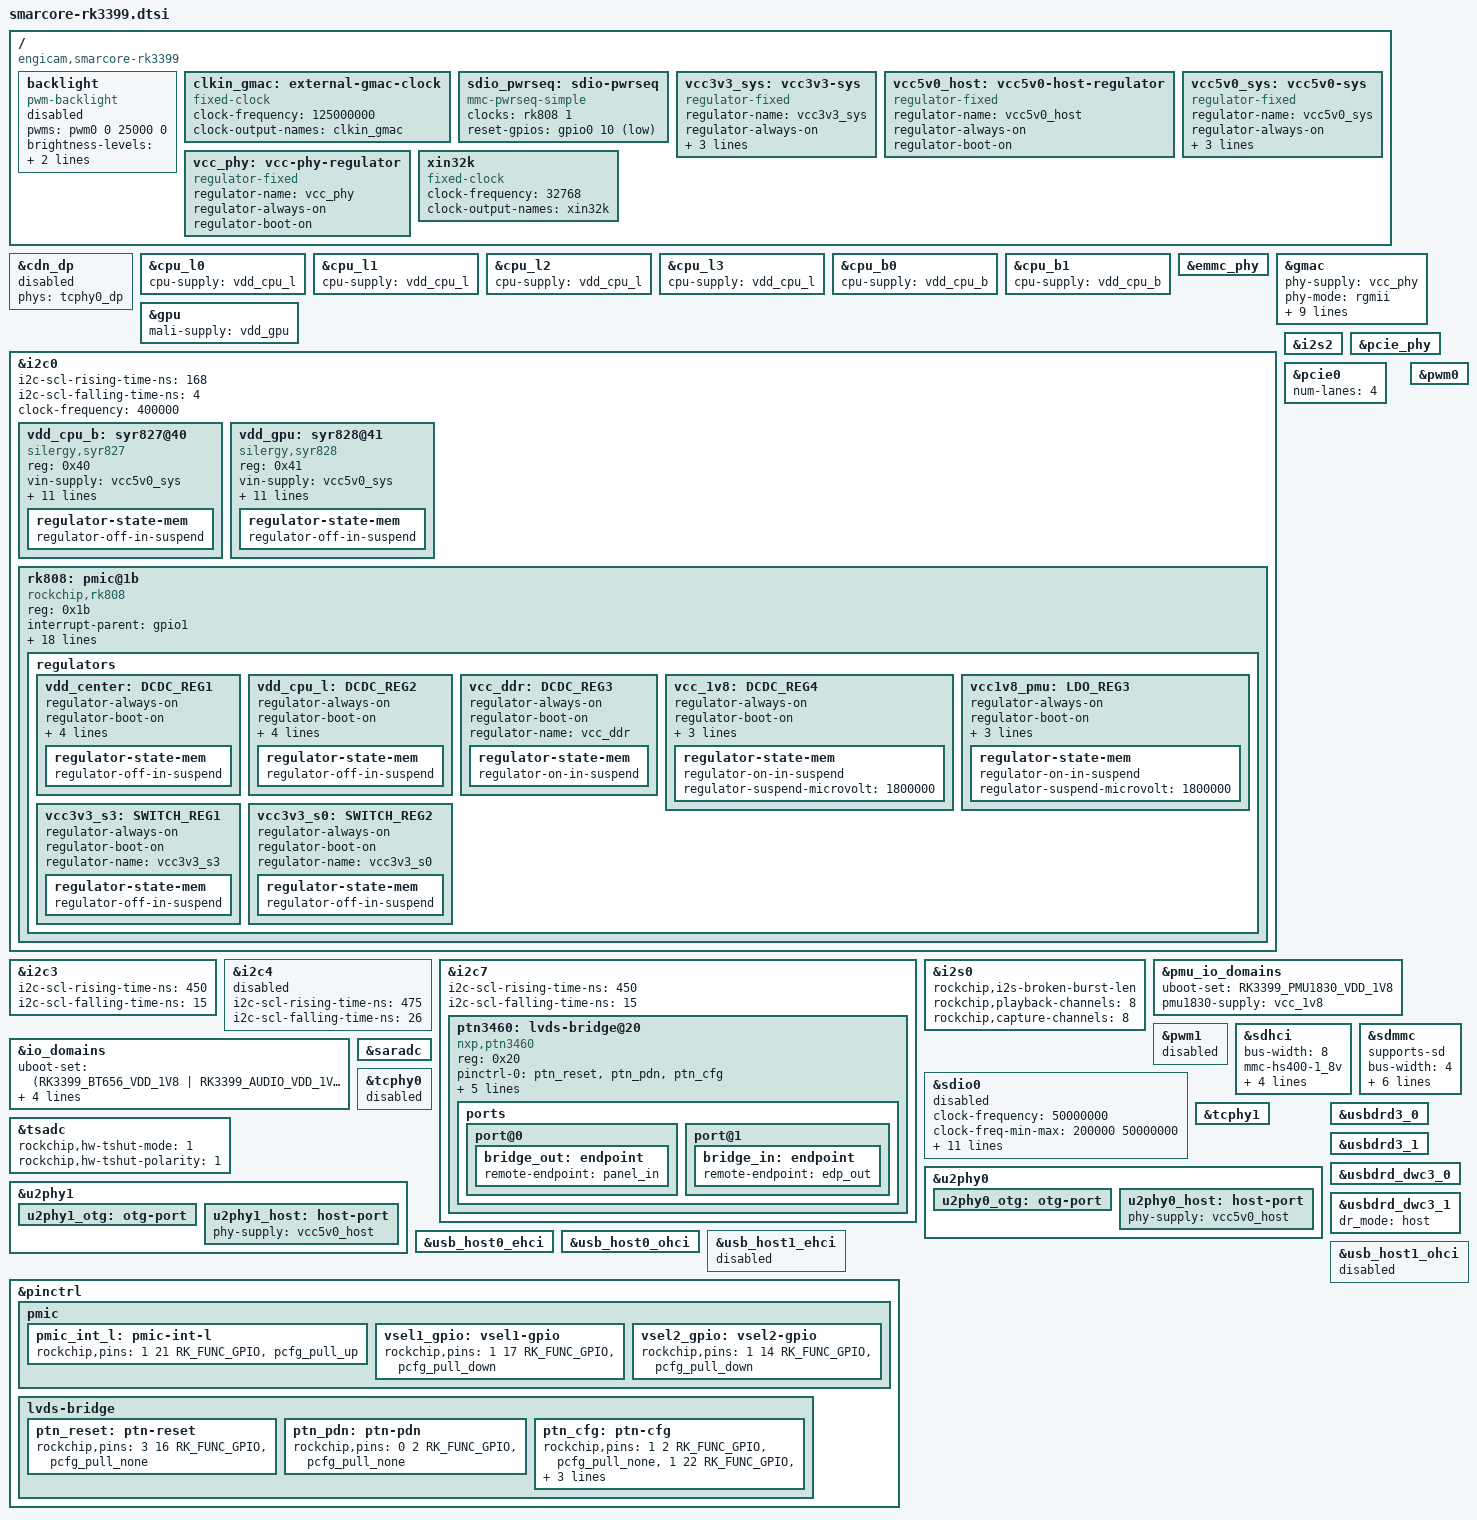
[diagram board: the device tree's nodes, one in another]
/*
 * Copyright (c) 2020 Engicam srl
 *
 * based on:
 * Copyright (c) 2016 Fuzhou Rockchip Electronics Co., Ltd
 *
 * This file is dual-licensed: you can use it either under the terms
 * of the GPL or the X11 license, at your option. Note that this dual
 * licensing only applies to this file, and not this project as a
 * whole.
 *
 *  a) This file is free software; you can redistribute it and/or
 *     modify it under the terms of the GNU General Public License as
 *     published by the Free Software Foundation; either version 2 of the
 *     License, or (at your option) any later version.
 *
 *     This file is distributed in the hope that it will be useful,
 *     but WITHOUT ANY WARRANTY; without even the implied warranty of
 *     MERCHANTABILITY or FITNESS FOR A PARTICULAR PURPOSE.  See the
 *     GNU General Public License for more details.
 *
 * Or, alternatively,
 *
 *  b) Permission is hereby granted, free of charge, to any person
 *     obtaining a copy of this software and associated documentation
 *     files (the "Software"), to deal in the Software without
 *     restriction, including without limitation the rights to use,
 *     copy, modify, merge, publish, distribute, sublicense, and/or
 *     sell copies of the Software, and to permit persons to whom the
 *     Software is furnished to do so, subject to the following
 *     conditions:
 *
 *     The above copyright notice and this permission notice shall be
 *     included in all copies or substantial portions of the Software.
 *
 *     THE SOFTWARE IS PROVIDED "AS IS", WITHOUT WARRANTY OF ANY KIND,
 *     EXPRESS OR IMPLIED, INCLUDING BUT NOT LIMITED TO THE WARRANTIES
 *     OF MERCHANTABILITY, FITNESS FOR A PARTICULAR PURPOSE AND
 *     NONINFRINGEMENT. IN NO EVENT SHALL THE AUTHORS OR COPYRIGHT
 *     HOLDERS BE LIABLE FOR ANY CLAIM, DAMAGES OR OTHER LIABILITY,
 *     WHETHER IN AN ACTION OF CONTRACT, TORT OR OTHERWISE, ARISING
 *     FROM, OUT OF OR IN CONNECTION WITH THE SOFTWARE OR THE USE OR
 *     OTHER DEALINGS IN THE SOFTWARE.
 */

#include "dt-bindings/pwm/pwm.h"
#include <dt-bindings/soc/rockchip-io-domain.h>
#include "rk3399.dtsi"
#include "../rockchip/rk3399-opp.dtsi"

/ {
	compatible = "engicam,smarcore-rk3399", "rockchip,rk3399";

	backlight: backlight {
		status = "disabled";
		compatible = "pwm-backlight";
		pwms = <&pwm0 0 25000 0>;
		brightness-levels = <
			  0   1   2   3   4   5   6   7
			  8   9  10  11  12  13  14  15
			 16  17  18  19  20  21  22  23
			 24  25  26  27  28  29  30  31
			 32  33  34  35  36  37  38  39
			 40  41  42  43  44  45  46  47
			 48  49  50  51  52  53  54  55
			 56  57  58  59  60  61  62  63
			 64  65  66  67  68  69  70  71
			 72  73  74  75  76  77  78  79
			 80  81  82  83  84  85  86  87
			 88  89  90  91  92  93  94  95
			 96  97  98  99 100 101 102 103
			104 105 106 107 108 109 110 111
			112 113 114 115 116 117 118 119
			120 121 122 123 124 125 126 127
			128 129 130 131 132 133 134 135
			136 137 138 139 140 141 142 143
			144 145 146 147 148 149 150 151
			152 153 154 155 156 157 158 159
			160 161 162 163 164 165 166 167
			168 169 170 171 172 173 174 175
			176 177 178 179 180 181 182 183
			184 185 186 187 188 189 190 191
			192 193 194 195 196 197 198 199
			200 201 202 203 204 205 206 207
			208 209 210 211 212 213 214 215
			216 217 218 219 220 221 222 223
			224 225 226 227 228 229 230 231
			232 233 234 235 236 237 238 239
			240 241 242 243 244 245 246 247
			248 249 250 251 252 253 254 255>;
		default-brightness-level = <200>;
	};

	clkin_gmac: external-gmac-clock {
		compatible = "fixed-clock";
		clock-frequency = <125000000>;
		clock-output-names = "clkin_gmac";
		#clock-cells = <0>;
	};

	sdio_pwrseq: sdio-pwrseq {
		compatible = "mmc-pwrseq-simple";
		clocks = <&rk808 1>;
		clock-names = "ext_clock";
//		pinctrl-names = "default";
//		pinctrl-0 = <&wifi_enable_h>;

		/*
		 * On the module itself this is one of these (depending
		 * on the actual card populated):
		 * - SDIO_RESET_L_WL_REG_ON
		 * - PDN (power down when low)
		 */
		reset-gpios = <&gpio0 10 GPIO_ACTIVE_LOW>; /* GPIO0_B2 */
	};

	vcc3v3_sys: vcc3v3-sys {
		compatible = "regulator-fixed";
		regulator-name = "vcc3v3_sys";
		regulator-always-on;
		regulator-boot-on;
		regulator-min-microvolt = <3300000>;
		regulator-max-microvolt = <3300000>;
	};

	vcc5v0_host: vcc5v0-host-regulator {
		compatible = "regulator-fixed";
		regulator-name = "vcc5v0_host";
		regulator-always-on;
		regulator-boot-on;
	};

	vcc5v0_sys: vcc5v0-sys {
		compatible = "regulator-fixed";
		regulator-name = "vcc5v0_sys";
		regulator-always-on;
		regulator-boot-on;
		regulator-min-microvolt = <5000000>;
		regulator-max-microvolt = <5000000>;
	};

	vcc_phy: vcc-phy-regulator {
		compatible = "regulator-fixed";
		regulator-name = "vcc_phy";
		regulator-always-on;
		regulator-boot-on;
	};

	xin32k: xin32k {
		compatible = "fixed-clock";
		clock-frequency = <32768>;
		clock-output-names = "xin32k";
		#clock-cells = <0>;
	};
};

&cdn_dp {
	phys = <&tcphy0_dp>;
	status = "disabled";
};

&cpu_l0 {
	cpu-supply = <&vdd_cpu_l>;
};

&cpu_l1 {
	cpu-supply = <&vdd_cpu_l>;
};

&cpu_l2 {
	cpu-supply = <&vdd_cpu_l>;
};

&cpu_l3 {
	cpu-supply = <&vdd_cpu_l>;
};

&cpu_b0 {
	cpu-supply = <&vdd_cpu_b>;
};

&cpu_b1 {
	cpu-supply = <&vdd_cpu_b>;
};

&emmc_phy {
	status = "okay";
};

&gmac {
	phy-supply = <&vcc_phy>;
	phy-mode = "rgmii";
	clock_in_out = "input";
	snps,reset-gpio = <&gpio3 15 GPIO_ACTIVE_LOW>;
	snps,reset-active-low;
	snps,reset-delays-us = <0 10000 50000>;
	assigned-clocks = <&cru SCLK_RMII_SRC>;
	assigned-clock-parents = <&clkin_gmac>;
	pinctrl-names = "default";
	pinctrl-0 = <&rgmii_pins>;
	tx_delay = <0x0>;
	rx_delay = <0x0>;
	status = "okay";
};

&gpu {
	status = "okay";
	mali-supply = <&vdd_gpu>;
};

&i2c0 {
	status = "okay";
	i2c-scl-rising-time-ns = <168>;
	i2c-scl-falling-time-ns = <4>;
	clock-frequency = <400000>;

	vdd_cpu_b: syr827@40 {
		compatible = "silergy,syr827";
		reg = <0x40>;
		vin-supply = <&vcc5v0_sys>;
		regulator-compatible = "fan53555-reg";
		pinctrl-names = "default";
		pinctrl-0 = <&vsel1_gpio>;
		vsel-gpios = <&gpio1 17 GPIO_ACTIVE_HIGH>;
		regulator-name = "vdd_cpu_b";
		regulator-min-microvolt = <712500>;
		regulator-max-microvolt = <1500000>;
		regulator-ramp-delay = <1000>;
		fcs,suspend-voltage-selector = <1>;
		regulator-always-on;
		regulator-boot-on;
		regulator-initial-state = <3>;
			regulator-state-mem {
			regulator-off-in-suspend;
		};
	};

	vdd_gpu: syr828@41 {
		compatible = "silergy,syr828";
		reg = <0x41>;
		vin-supply = <&vcc5v0_sys>;
		regulator-compatible = "fan53555-reg";
		pinctrl-names = "default";
		pinctrl-0 = <&vsel2_gpio>;
		vsel-gpios = <&gpio1 14 GPIO_ACTIVE_HIGH>;
		regulator-name = "vdd_gpu";
		regulator-min-microvolt = <712500>;
		regulator-max-microvolt = <1500000>;
		regulator-ramp-delay = <1000>;
		fcs,suspend-voltage-selector = <1>;
		regulator-always-on;
		regulator-boot-on;
		regulator-initial-state = <3>;
			regulator-state-mem {
			regulator-off-in-suspend;
		};
	};

	rk808: pmic@1b {
		compatible = "rockchip,rk808";
		reg = <0x1b>;
		interrupt-parent = <&gpio1>;
		interrupts = <21 IRQ_TYPE_LEVEL_LOW>;
		pinctrl-names = "default";
		pinctrl-0 = <&pmic_int_l>;
		rockchip,system-power-controller;
		wakeup-source;
		#clock-cells = <1>;
		clock-output-names = "rk808-clkout1", "rk808-clkout2";

		vcc1-supply = <&vcc5v0_sys>;
		vcc2-supply = <&vcc5v0_sys>;
		vcc3-supply = <&vcc5v0_sys>;
		vcc4-supply = <&vcc5v0_sys>;
		vcc6-supply = <&vcc3v3_sys>;
		vcc7-supply = <&vcc3v3_sys>;
		vcc8-supply = <&vcc3v3_sys>;
		vcc9-supply = <&vcc3v3_sys>;
		vcc10-supply = <&vcc3v3_sys>;
		vcc11-supply = <&vcc3v3_sys>;
		vcc12-supply = <&vcc3v3_sys>;
		vddio-supply = <&vcc_1v8>;

		regulators {
			vdd_center: DCDC_REG1 {
				regulator-always-on;
				regulator-boot-on;
				regulator-min-microvolt = <750000>;
				regulator-max-microvolt = <1350000>;
				regulator-ramp-delay = <6001>;
				regulator-name = "vdd_center";
				regulator-state-mem {
					regulator-off-in-suspend;
				};
			};

			vdd_cpu_l: DCDC_REG2 {
				regulator-always-on;
				regulator-boot-on;
				regulator-min-microvolt = <750000>;
				regulator-max-microvolt = <1350000>;
				regulator-ramp-delay = <6001>;
				regulator-name = "vdd_cpu_l";
				regulator-state-mem {
					regulator-off-in-suspend;
				};
			};

			vcc_ddr: DCDC_REG3 {
				regulator-always-on;
				regulator-boot-on;
				regulator-name = "vcc_ddr";
				regulator-state-mem {
					regulator-on-in-suspend;
				};
			};

			vcc_1v8: DCDC_REG4 {
				regulator-always-on;
				regulator-boot-on;
				regulator-min-microvolt = <1800000>;
				regulator-max-microvolt = <1800000>;
				regulator-name = "vcc_1v8";
				regulator-state-mem {
					regulator-on-in-suspend;
					regulator-suspend-microvolt = <1800000>;
				};
			};

			vcc1v8_pmu: LDO_REG3 {
				regulator-always-on;
				regulator-boot-on;
				regulator-min-microvolt = <1800000>;
				regulator-max-microvolt = <1800000>;
				regulator-name = "vcc1v8_pmu";
				regulator-state-mem {
					regulator-on-in-suspend;
					regulator-suspend-microvolt = <1800000>;
				};
			};


			vcc3v3_s3: SWITCH_REG1 {
				regulator-always-on;
				regulator-boot-on;
				regulator-name = "vcc3v3_s3";
				regulator-state-mem {
					regulator-off-in-suspend;
				};
			};

			vcc3v3_s0: SWITCH_REG2 {
				regulator-always-on;
				regulator-boot-on;
				regulator-name = "vcc3v3_s0";
				regulator-state-mem {
					regulator-off-in-suspend;
				};
			};
		};
	};
};

&i2c3 {
	status = "okay";
	i2c-scl-rising-time-ns = <450>;
	i2c-scl-falling-time-ns = <15>;
};

&i2c4 {
	status = "disabled";
	i2c-scl-rising-time-ns = <475>;
	i2c-scl-falling-time-ns = <26>;

};

&i2c7 {
	status = "okay";
	i2c-scl-rising-time-ns = <450>;
	i2c-scl-falling-time-ns = <15>;

	ptn3460: lvds-bridge@20 {
		compatible = "nxp,ptn3460";
		reg = <0x20>;
		pinctrl-names = "default";
		pinctrl-0 = <&ptn_reset &ptn_pdn &ptn_cfg>;
		powerdown-gpios = <&gpio0 2 GPIO_ACTIVE_HIGH>;
		reset-gpios = <&gpio3 16 GPIO_ACTIVE_HIGH>;
		edid-emulation = <0>;
		enable-gpios = <&gpio1 2 GPIO_ACTIVE_LOW>, /* CFG1 */
				<&gpio1 22 GPIO_ACTIVE_LOW>, /* CFG2 */
				<&gpio1 18 GPIO_ACTIVE_LOW>, /* CFG3 */
				<&gpio1 20 GPIO_ACTIVE_LOW>; /* CFG4 */

		ports {
			#address-cells = <1>;
			#size-cells = <0>;

			port@0 {
				bridge_out: endpoint {
					remote-endpoint = <&panel_in>;
				};
			};

			port@1 {
				bridge_in: endpoint {
					remote-endpoint = <&edp_out>;
				};
			};
		};
	};

};

&i2s0 {
	status = "okay";
	rockchip,i2s-broken-burst-len;
	rockchip,playback-channels = <8>;
	rockchip,capture-channels = <8>;
	#sound-dai-cells = <0>;
};

&i2s2 {
	#sound-dai-cells = <0>;
	status = "okay";
};

&io_domains {
	status = "okay";

	/*
	 * If the uboot use rkdevelop branch, the io-domain is not set
	 * during uboot phase, it will cause the io voltage is not suit for
	 * the hardware,maybe will damage the io of rk3399, so we add
	 * uboot-set value to make sure the value is same with the kernel,
	 * ofcause you must make sure firstly the value here is suit for your
	 * hardware. The available value is defined in
	 * include/dt-bindings/soc/rockchip-io-domain.h, they are
	 * also list here for more convenient configuration:
	 * bt656-supply: RK3399_BT656_VDD_1V8 or RK3399_BT656_VDD_3V3
	 * audio-supply: RK3399_AUDIO_VDD_1V8 or RK3399_AUDIO_VDD_3V3
	 * gpio1830-supply: RK3399_GPIO1833_VDD_1V8 or RK3399_GPIO1833_VDD_3V3
	 * sdmmc-supply: don't need to configure because the voltage
	 *                       is set in source code during runtime.
	 * NOTE:
	 * 1. The value in uboot-set must be enclosed in "()", otherwise will
	 *     cause compile error.
	 * 2. The uboot-set configuration must be cooperated with submit
	 *     in u-boot.
	 */

	uboot-set = <(RK3399_BT656_VDD_1V8 | RK3399_AUDIO_VDD_1V8 |
				RK3399_GPIO1833_VDD_1V8 | RK3399_SDMMC_VDD_1V8)>;
	bt656-supply = <&vcc_1v8>;		/* bt656_gpio2ab_ms */
	audio-supply = <&vcc_1v8>;	/* audio_gpio3d4a_ms */
	sdmmc-supply = <&vcc_1v8>;		/* sdmmc_gpio4b_ms */
	gpio1830-supply = <&vcc_1v8>;		/* gpio1833_gpio4cd_ms */
};

&pcie_phy {
	status = "okay";
};

&pcie0 {
	num-lanes = <4>;
	status = "okay";
};

&pmu_io_domains {
	status = "okay";
	/*
	 * If the uboot use rkdevelop branch, the pmu_io_domain is not set
	 * during uboot phase, it will cause the io voltage is not suit for
	 * the hardware,maybe will damage the io of rk3399, so we add
	 * uboot-set value to make sure the value is same with the kernel,
	 * ofcause you must make sure firstly the value here is suit for your
	 * hardware. The available value is defined in
	 * include/dt-bindings/soc/rockchip-io-domain.h, they are
	 * also list here for more convenient configuration:
	 * pmu1830-supply: RK3399_PMU1830_VDD_1V8 or RK3399_PMU1830_VDD_3V0
	 */
	uboot-set = <RK3399_PMU1830_VDD_1V8>;
	pmu1830-supply = <&vcc_1v8>;
};

&pwm0 {
	status = "okay";
};

&pwm1 {
	status = "disabled";
};

&sdhci {
	bus-width = <8>;
	mmc-hs400-1_8v;
	supports-emmc;
	non-removable;
	keep-power-in-suspend;
	mmc-hs400-enhanced-strobe;
	status = "okay";
};

&sdio0 {
	clock-frequency = <50000000>;
	clock-freq-min-max = <200000 50000000>;
	supports-sdio;
	bus-width = <4>;
	disable-wp;
	cap-sd-highspeed;
	cap-sdio-irq;
	keep-power-in-suspend;
	mmc-pwrseq = <&sdio_pwrseq>;
	non-removable;
	num-slots = <1>;
	pinctrl-names = "default";
	pinctrl-0 = <&sdio0_bus4 &sdio0_cmd &sdio0_clk>;
	sd-uhs-sdr104;
	status = "disabled";
};

&sdmmc {
//	clock-frequency = <150000000>;
//	clock-freq-min-max = <100000 150000000>;
//	max-frequency = <5000000>;
	supports-sd;
	bus-width = <4>;
	non-removable;	/* da togliere solo per debug */
	no-1-8-v;
//	cap-mmc-highspeed;
//	cap-sd-highspeed;
	disable-wp;
	num-slots = <1>;
	//sd-uhs-sdr104;
//	vmmc-supply = <&vcc_sd>;
//	vqmmc-supply = <&vccio_sd>;
	pinctrl-names = "default";
	pinctrl-0 = <&sdmmc_clk &sdmmc_cmd &sdmmc_cd &sdmmc_bus4>;
	status = "okay";
};

&saradc {
	status = "okay";
};

&tcphy0 {
	status = "disabled";
};

&tcphy1 {
	status = "okay";
};

&tsadc {
	/* tshut mode 0:CRU 1:GPIO */
	rockchip,hw-tshut-mode = <1>;
	/* tshut polarity 0:LOW 1:HIGH */
	rockchip,hw-tshut-polarity = <1>;
	status = "okay";
};

&u2phy0 {
	status = "okay";

	u2phy0_otg: otg-port {
		status = "okay";
	};

	u2phy0_host: host-port {
		phy-supply = <&vcc5v0_host>;
		status = "okay";
	};
};

&u2phy1 {
	status = "okay";

	u2phy1_otg: otg-port {
		status = "okay";
	};

	u2phy1_host: host-port {
		phy-supply = <&vcc5v0_host>;
		status = "okay";
	};
};

&usbdrd3_0 {
	status = "okay";
};

&usbdrd3_1 {
	status = "okay";
};

&usbdrd_dwc3_0 {
	status = "okay";
};

&usbdrd_dwc3_1 {
	status = "okay";
	dr_mode = "host";
};

&usb_host0_ehci {
	status = "okay";
};

&usb_host0_ohci {
	status = "okay";
};

&usb_host1_ehci {
	status = "disabled";
};

&usb_host1_ohci {
	status = "disabled";
};

&pinctrl {
	pmic {
		pmic_int_l: pmic-int-l {
			rockchip,pins =
				<1 21 RK_FUNC_GPIO &pcfg_pull_up>;
		};
		vsel1_gpio: vsel1-gpio {
			rockchip,pins =
				<1 17 RK_FUNC_GPIO &pcfg_pull_down>;
		};
		vsel2_gpio: vsel2-gpio {
			rockchip,pins =
				<1 14 RK_FUNC_GPIO &pcfg_pull_down>;
		};
	};

	lvds-bridge {
		ptn_reset: ptn-reset {
			rockchip,pins =
				<3 16 RK_FUNC_GPIO &pcfg_pull_none>;
		};

		ptn_pdn: ptn-pdn {
			rockchip,pins =
				<0 2 RK_FUNC_GPIO &pcfg_pull_none>;
		};

		ptn_cfg: ptn-cfg {
			rockchip,pins =
				<1 2 RK_FUNC_GPIO &pcfg_pull_none>,  /* CFG1 */
				<1 22 RK_FUNC_GPIO &pcfg_pull_down>, /* CFG2 */
				<1 18 RK_FUNC_GPIO &pcfg_pull_none>, /* CFG3 */
				<1 20 RK_FUNC_GPIO &pcfg_pull_none>; /* CFG4 */
		};

	};

};
